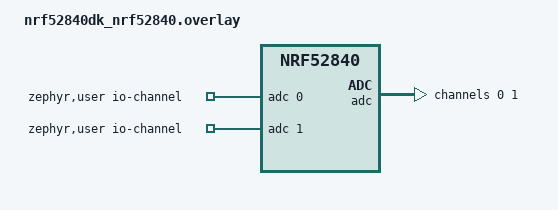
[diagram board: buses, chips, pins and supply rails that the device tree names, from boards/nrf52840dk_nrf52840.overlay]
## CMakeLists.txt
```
#
# Copyright (c) 2024 Nordic Semiconductor
#
# SPDX-License-Identifier: LicenseRef-Nordic-5-Clause
#

cmake_minimum_required(VERSION 3.20.0)
find_package(Zephyr REQUIRED HINTS $ENV{ZEPHYR_BASE})

project(GDP)

target_sources(app PRIVATE
  src/main.c
  src/my_lbs.c
)
```

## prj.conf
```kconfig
#
# Copyright (c) 2024 Nordic Semiconductor
#
# SPDX-License-Identifier: LicenseRef-Nordic-5-Clause
#

# Logger module
CONFIG_LOG=y

# Configure your preferred connection parameters
CONFIG_BT_PERIPHERAL_PREF_MIN_INT=800
CONFIG_BT_PERIPHERAL_PREF_MAX_INT=800
CONFIG_BT_PERIPHERAL_PREF_LATENCY=0
CONFIG_BT_PERIPHERAL_PREF_TIMEOUT=400
# CONFIG_BT_GAP_AUTO_UPDATE_CONN_PARAMS=y // Me: this is set to y by default

# Enable nrfx drivers #
CONFIG_NRFX_SAADC=y
CONFIG_NRFX_PPI=y
#CONFIG_NRFX_DPPI=y
CONFIG_NRFX_TIMER2=y

# Button and LED library
CONFIG_DK_LIBRARY=y

# Bluetooth LE
CONFIG_BT=y
CONFIG_BT_PERIPHERAL=y
CONFIG_BT_DEVICE_NAME="DK_Group12"
CONFIG_BT_AUTO_PHY_UPDATE=n
CONFIG_BT_GATT_CLIENT=y
CONFIG_BT_SMP=y
CONFIG_BT_SMP_APP_PAIRING_ACCEPT=y

# Update Data Length and MTU
CONFIG_BT_USER_DATA_LEN_UPDATE=y
CONFIG_BT_CTLR_DATA_LENGTH_MAX=207 # was 251
CONFIG_BT_BUF_ACL_RX_SIZE=207 # was 251
CONFIG_BT_BUF_ACL_TX_SIZE=207 # was 251
CONFIG_BT_L2CAP_TX_MTU=203 # MTU for an L2CAP PDU. i.e., gatt mtu. Now data is size 200, was 247 before
# payload mtu = data. gatt mtu = payload mtu + attribute header (3 bytes)

# Configure the NFC things
CONFIG_NFC_T4T_NRFXLIB=y
CONFIG_NFC_NDEF=y
CONFIG_NFC_NDEF_MSG=y
CONFIG_NFC_NDEF_RECORD=y
CONFIG_NFC_NDEF_LE_OOB_REC=y
CONFIG_NFC_NDEF_CH_MSG=y

CONFIG_NFC_NDEF_TNEP_RECORD=y
CONFIG_NFC_TNEP_TAG=y
CONFIG_NFC_NDEF_PARSER=y
CONFIG_NFC_NDEF_CH_PARSER=y
CONFIG_NFC_NDEF_LE_OOB_REC_PARSER=y
CONFIG_NFC_TNEP_CH=y

# Bonding and persistent storage for pairing data (e.g., keys)
CONFIG_BT_SETTINGS=y
CONFIG_FLASH=y
CONFIG_FLASH_PAGE_LAYOUT=y
CONFIG_FLASH_MAP=y
CONFIG_NVS=y
CONFIG_SETTINGS=y

# Polling
CONFIG_POLL=y

# Increase stack size for the main thread and System Workqueue, NFC uses stack size of 3072
CONFIG_SYSTEM_WORKQUEUE_STACK_SIZE=2048
CONFIG_MAIN_STACK_SIZE=3072
```

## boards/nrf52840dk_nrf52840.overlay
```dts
// To get started, press Ctrl+Space to bring up the completion menu and view the available nodes.

// You can also use the buttons in the sidebar to perform actions on nodes.
// Actions currently available include:

// * Enabling / disabling the node
// * Adding the bus to a bus
// * Removing the node
// * Connecting ADC channels

// For more help, browse the DeviceTree documentation at https://docs.zephyrproject.org/latest/guides/dts/index.html
// You can also visit the nRF DeviceTree extension documentation at https://docs.nordicsemi.com/bundle/nrf-connect-vscode/page/guides/ncs_configure_app.html#devicetree-support-in-the-extension

/ {
	zephyr,user {
		io-channels = <&adc 0>, <&adc 1>;
	};
};

/* Configure the ADC channel  */
&adc {
	#address-cells = <1>;
	#size-cells = <0>;
	status = "okay";

	channel@0 {
		reg = <0>;
		zephyr,gain = "ADC_GAIN_1_6";
		zephyr,reference = "ADC_REF_INTERNAL";
		zephyr,acquisition-time = <ADC_ACQ_TIME_DEFAULT>;
		zephyr,input-positive = <NRF_SAADC_AIN0>; /* P0.02 for nRF52xx, P0.04 for nRF5340 */
		zephyr,input-negative = <NRF_SAADC_AIN1>; /* P0.03 for nRF52xx */
		zephyr,resolution = <12>;
	};

	channel@1 {
		reg = <1>;
		zephyr,gain = "ADC_GAIN_1_6";
		zephyr,reference = "ADC_REF_INTERNAL";
		zephyr,acquisition-time = <ADC_ACQ_TIME_DEFAULT>;
		zephyr,input-positive = <NRF_SAADC_AIN2>; /* P0.04 for nRF52xx */
		zephyr,input-negative = <NRF_SAADC_AIN4>; /* P0.28 for nRF52xx */
		zephyr,resolution = <12>;
	};
};
```

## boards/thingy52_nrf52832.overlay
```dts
// To get started, press Ctrl+Space to bring up the completion menu and view the available nodes.

// You can also use the buttons in the sidebar to perform actions on nodes.
// Actions currently available include:

// * Enabling / disabling the node
// * Adding the bus to a bus
// * Removing the node
// * Connecting ADC channels

// For more help, browse the DeviceTree documentation at https://docs.zephyrproject.org/latest/guides/dts/index.html
// You can also visit the nRF DeviceTree extension documentation at https://docs.nordicsemi.com/bundle/nrf-connect-vscode/page/guides/ncs_configure_app.html#devicetree-support-in-the-extension

/ {
	zephyr,user {
		io-channels = <&adc 0>, <&adc 1>;
	};
};

/* Configure the ADC channel  */
&adc {
	#address-cells = <1>;
	#size-cells = <0>;
	status = "okay";

	channel@0 {
		reg = <0>;
		zephyr,gain = "ADC_GAIN_1_6";
		zephyr,reference = "ADC_REF_INTERNAL";
		zephyr,acquisition-time = <ADC_ACQ_TIME_DEFAULT>;
		zephyr,input-positive = <NRF_SAADC_AIN0>; /* P0.02 for thingy52 */
		zephyr,input-negative = <NRF_SAADC_AIN2>; /* P0.04 for thingy52 */
		zephyr,resolution = <12>;
	};
};
```

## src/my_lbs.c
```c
/*
 * Copyright (c) 2018 Nordic Semiconductor ASA
 *
 * SPDX-License-Identifier: LicenseRef-Nordic-5-Clause
 */

/** @file
 *  @brief LED Button Service (LBS) sample
 */



#include <zephyr/types.h>
#include <stddef.h>
#include <string.h>
#include <errno.h>
#include <zephyr/sys/printk.h>
#include <zephyr/sys/byteorder.h>
#include <zephyr/kernel.h>
#include <zephyr/logging/log.h>
#include <zephyr/sys/printk.h> // Extra to print out received data. Not logging

#include <zephyr/bluetooth/bluetooth.h>
#include <zephyr/bluetooth/hci.h>
#include <zephyr/bluetooth/conn.h>
#include <zephyr/bluetooth/uuid.h>
#include <zephyr/bluetooth/gatt.h>

#include "my_lbs.h"

static bool notify_mysensor_enabled;

/* Define the configuration change callback function for the MYSENSOR characteristic */
static void mylbsbc_ccc_mysensor_cfg_changed(const struct bt_gatt_attr *attr,uint16_t value)
{
	notify_mysensor_enabled = (value == BT_GATT_CCC_NOTIFY);
}

static uint8_t writable_value[20]; // Me: Buffer for the characteristic value
static ssize_t received_app_data(struct bt_conn *conn, const struct bt_gatt_attr *attr, const void *buf, uint16_t len, uint16_t offset, uint8_t flags){
	
	
	uint8_t *value = attr -> user_data;

	if(offset + len > sizeof(writable_value)){
		return BT_GATT_ERR(BT_ATT_ERR_INVALID_OFFSET);
	}

	memcpy(value + offset, buf, len);
	printk("Characteristic written, new value: ");
	for(int i=0; i<len; i++){
		printk("%d", ((uint8_t *)buf)[i]);
	}
	printk("\n");

	return len;
}

/* LED Button Service Declaration */
BT_GATT_SERVICE_DEFINE(
	my_lbs_svc, BT_GATT_PRIMARY_SERVICE(BT_UUID_LBS),
	/* Create and add the MYSENSOR characteristic and its CCCD  */
	BT_GATT_CHARACTERISTIC(BT_UUID_LBS_MYSENSOR,
			       BT_GATT_CHRC_NOTIFY,
			       BT_GATT_PERM_NONE, NULL, NULL,
			       NULL),

	BT_GATT_CCC(mylbsbc_ccc_mysensor_cfg_changed,
		    BT_GATT_PERM_READ | BT_GATT_PERM_WRITE),

	/* Characteristic that receives the app data */
	BT_GATT_CHARACTERISTIC(BT_UUID_APP_DATA, BT_GATT_CHRC_WRITE, BT_GATT_PERM_WRITE, NULL, received_app_data, writable_value),
);


/* Define the function to send notifications for the MYSENSOR characteristic */
int my_lbs_send_sensor_notify(uint32_t* sensor_value, size_t data_size)
{
	if (!notify_mysensor_enabled) {
		return -EACCES;
	}

	

	return bt_gatt_notify(NULL, &my_lbs_svc.attrs[2], 
			      sensor_value,
			      data_size);
}
```

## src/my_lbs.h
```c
/*
 * Copyright (c) 2018 Nordic Semiconductor ASA
 *
 * SPDX-License-Identifier: LicenseRef-Nordic-5-Clause
 */

#ifndef BT_LBS_H_
#define BT_LBS_H_

/**@file
 * @defgroup bt_lbs LED Button Service API
 * @{
 * @brief API for the LED Button Service (LBS).
 */

#ifdef __cplusplus
extern "C" {
#endif

#include <zephyr/types.h>

/** @brief LBS Service UUID. */
#define BT_UUID_LBS_VAL BT_UUID_128_ENCODE(0xa5c298c0,0xa235,0x4a32,0xa4e9,0x5b42f6bd50e5)
#define BT_UUID_LBS BT_UUID_DECLARE_128(BT_UUID_LBS_VAL)

/* Assign a UUID to the MYSENSOR characteristic */
#define BT_UUID_LBS_MYSENSOR_VAL BT_UUID_128_ENCODE(0xa5c298c1,0xa235,0x4a32,0xa4e9,0x5b42f6bd50e5)
#define BT_UUID_LBS_MYSENSOR BT_UUID_DECLARE_128(BT_UUID_LBS_MYSENSOR_VAL)

/** @brief App data Characteristic UUID. */
#define BT_UUID_APP_DATA_VAL BT_UUID_128_ENCODE(0xa5c298c2,0xa235,0x4a32,0xa4e9,0x5b42f6bd50e5)
#define BT_UUID_APP_DATA BT_UUID_DECLARE_128(BT_UUID_APP_DATA_VAL)

/** @brief Send the sensor value as notification.
 *
 * This function sends an uint32_t  value, typically the value
 * of a simulated sensor to all connected peers.
 *
 * @param[in] sensor_value The value of the simulated sensor.
 *
 * @retval 0 If the operation was successful.
 *           Otherwise, a (negative) error code is returned.
 */
int my_lbs_send_sensor_notify(uint32_t* sensor_value, size_t data_size);

#ifdef __cplusplus
}
#endif

/**
 * @}
 */

#endif /* BT_LBS_H_ */
```
